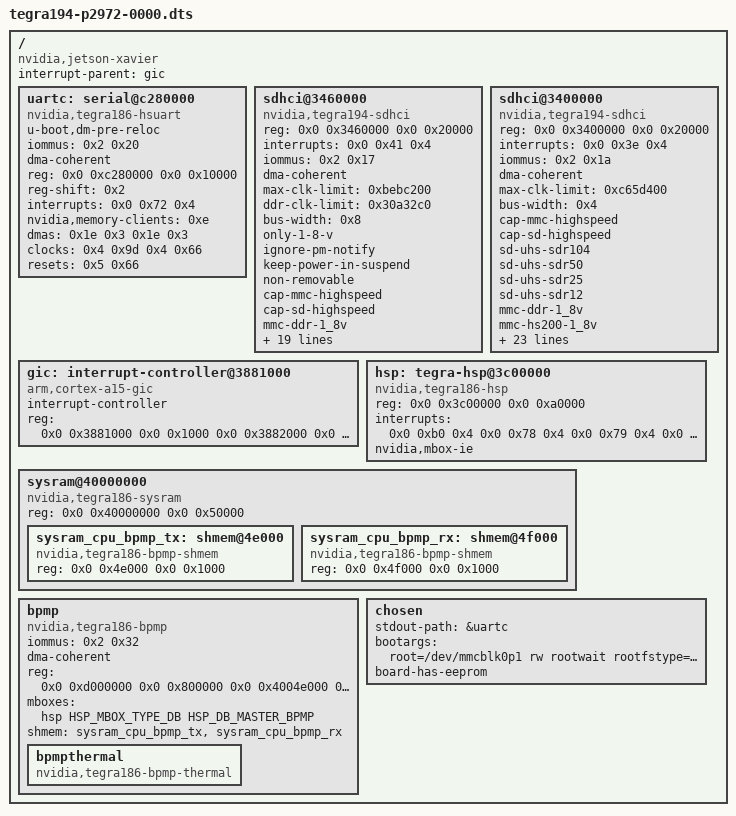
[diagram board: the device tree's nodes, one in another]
#include <dt-bindings/mailbox/tegra186-hsp.h>

/dts-v1/;
/ {
	compatible = "nvidia,jetson-xavier", "nvidia,tegra194";
	interrupt-parent = <&gic>;
	#address-cells = <2>;
	#size-cells = <2>;

	uartc: serial@c280000 {
		u-boot,dm-pre-reloc;
		compatible = "nvidia,tegra186-hsuart", "nvidia,tegra20-uart";
		iommus = <0x2 0x20>;
		dma-coherent;
		reg = <0x0 0xc280000 0x0 0x10000>;
		reg-shift = <0x2>;
		interrupts = <0x0 0x72 0x4>;
		nvidia,memory-clients = <0xe>;
		dmas = <0x1e 0x3 0x1e 0x3>;
		dma-names = "rx", "tx";
		clocks = <0x4 0x9d 0x4 0x66>;
		clock-names = "serial", "parent";
		resets = <0x5 0x66>;
		reset-names = "serial";
		status = "okay";
		linux,phandle = <0x169>;
		phandle = <0x169>;
	};

	sdhci@3460000 {
		compatible = "nvidia,tegra194-sdhci";
		reg = <0x0 0x3460000 0x0 0x20000>;
		interrupts = <0x0 0x41 0x4>;
		iommus = <0x2 0x17>;
		dma-coherent;
		max-clk-limit = <0xbebc200>;
		ddr-clk-limit = <0x30a32c0>;
		bus-width = <0x8>;
		only-1-8-v;
		ignore-pm-notify;
		keep-power-in-suspend;
		non-removable;
		cap-mmc-highspeed;
		cap-sd-highspeed;
		mmc-ddr-1_8v;
		mmc-hs200-1_8v;
		mmc-hs400-1_8v;
		mmc-hs400-enhanced-strobe;
		nvidia,min-tap-delay = <0x60>;
		nvidia,max-tap-delay = <0x8b>;
		nvidia,en-periodic-cflush;
		nvidia,periodic-cflush-to = <0xa>;
		resets = <&bpmp 0x55>;
		reset-names = "sdhci";
		pll_source = "pll_p", "pll_c4_out0_lj";
		nvidia,set-parent-clk;
		nvidia,parent_clk_list = "pll_p", "pll_p", "NULL", "NULL", "NULL", "NULL", "NULL", "NULL", "pll_p", "pll_c4_out0_lj", "pll_c4_out0_lj";
		clocks = <&bpmp 0x7b &bpmp 0x66 &bpmp 0xed &bpmp 0xdb>;
		clock-names = "sdmmc", "pll_p", "pll_c4_out0_lj", "sdmmc_legacy_tm";
		status = "okay";
		uhs-mask = <0x0>;
		nvidia,enable-hwcq;
		vmmc-supply = <0x20>;
		vqmmc-supply = <0x1d>;
	};

	sdhci@3400000 {
		compatible = "nvidia,tegra194-sdhci";
		reg = <0x0 0x3400000 0x0 0x20000>;
		interrupts = <0x0 0x3e 0x4>;
		iommus = <0x2 0x1a>;
		dma-coherent;
		max-clk-limit = <0xc65d400>;
		bus-width = <0x4>;
		cap-mmc-highspeed;
		cap-sd-highspeed;
		sd-uhs-sdr104;
		sd-uhs-sdr50;
		sd-uhs-sdr25;
		sd-uhs-sdr12;
		mmc-ddr-1_8v;
		mmc-hs200-1_8v;
		nvidia,vqmmc-always-on;
		cd-inverted;
		nvidia,min-tap-delay = <0x60>;
		nvidia,max-tap-delay = <0x8b>;
		pwrdet-support;
		pinctrl-names = "sdmmc_e_33v_enable", "sdmmc_e_33v_disable";
		pinctrl-0 = <0x23>;
		pinctrl-1 = <0x24>;
		ignore-pm-notify;
		resets = <&bpmp 0x52>;
		reset-names = "sdhci";
		pll_source = "pll_p", "pll_c4_muxed";
		nvidia,set-parent-clk;
		nvidia,parent_clk_list = "pll_p", "pll_p", "pll_p", "pll_p", "pll_p", "pll_c4_muxed", "pll_c4_muxed", "pll_c4_muxed", "pll_c4_muxed", "pll_c4_muxed", "NULL";
		clocks = <&bpmp 0x78 &bpmp 0x66 &bpmp 0xf1 &bpmp 0xdb>;
		clock-names = "sdmmc", "pll_p", "pll_c4_muxed", "sdmmc_legacy_tm";
		uhs-mask = <0x8>;
		nvidia,en-periodic-calib;
		status = "okay";
		mmc-ocr-mask = <0x0>;
		cd-gpios = <0x13 0x37 0x0>;
		nvidia,cd-wakeup-capable;
		vmmc-supply = <0x25>;
	};

	gic: interrupt-controller@3881000 {
		compatible = "arm,cortex-a15-gic";
		#interrupt-cells = <0x3>;
		interrupt-controller;
		reg = <0x0 0x3881000 0x0 0x1000 0x0 0x3882000 0x0 0x2000>;
		status = "okay";
	};

	hsp: tegra-hsp@3c00000 {
		compatible = "nvidia,tegra186-hsp";
		reg = <0x0 0x3c00000 0x0 0xa0000>;
		interrupts = <0x0 0xb0 0x4 0x0 0x78 0x4 0x0 0x79 0x4 0x0 0x7a 0x4 0x0 0x7b 0x4 0x0 0x7c 0x4 0x0 0x7d 0x4 0x0 0x7e 0x4 0x0 0x7f 0x4>;
		interrupt-names = "doorbell", "shared0", "shared1", "shared2", "shared3", "shared4", "shared5", "shared6", "shared7";
		nvidia,mbox-ie;
		status = "okay";
		linux,phandle = <0x1cd>;
		phandle = <0x1cd>;
		#mbox-cells = <0x2>;
	};

	sysram@40000000 {
		compatible = "nvidia,tegra186-sysram", "mmio-sram";
		reg = <0x0 0x40000000 0x0 0x50000>;
		#address-cells = <2>;
		#size-cells = <2>;
		ranges = <0 0x0 0x0 0x40000000 0x0 0x50000>;

		sysram_cpu_bpmp_tx: shmem@4e000 {
			compatible = "nvidia,tegra186-bpmp-shmem";
			reg = <0x0 0x4e000 0x0 0x1000>;
		};

		sysram_cpu_bpmp_rx: shmem@4f000 {
			compatible = "nvidia,tegra186-bpmp-shmem";
			reg = <0x0 0x4f000 0x0 0x1000>;
		};
	};

	bpmp: bpmp {
		compatible = "nvidia,tegra186-bpmp";
		iommus = <0x2 0x32>;
		dma-coherent;
		reg = <0x0 0xd000000 0x0 0x800000 0x0 0x4004e000 0x0 0x1000 0x0 0x4004f000 0x0 0x1000>;
		status = "okay";
		#power-domain-cells = <0x1>;
		#clock-cells = <0x1>;
		#reset-cells = <0x1>;
		#strap-cells = <0x1>;
		#nvidia,controller-id-cells = <0x1>;

		mboxes = <&hsp HSP_MBOX_TYPE_DB HSP_DB_MASTER_BPMP>;
		shmem = <&sysram_cpu_bpmp_tx &sysram_cpu_bpmp_rx>;

		bpmpthermal {
			compatible = "nvidia,tegra186-bpmp-thermal";
			#thermal-sensor-cells = <0x1>;
			status = "okay";
			linux,phandle = <0xb8>;
			phandle = <0xb8>;
		};
	};

    chosen {
		stdout-path = &uartc;
		bootargs = "root=/dev/mmcblk0p1 rw rootwait rootfstype=ext4 console=ttyTCU0,115200n8 console=tty0 fbcon=map:0 net.ifnames=0 rootfstype=ext4  ";
		board-has-eeprom;
	};
};
